# MKW38A4 register map
Vendor: NXP Semiconductors; Series: Kinetis_W; File version: 1.6
CPU: CM0PLUS r0p0, little endian, no MPU, no FPU, VTOR, 2 interrupt priority bits
Registers are 32-bit, read-write, no defined reset value unless marked. A register's access mark holds for its fields unless they carry their own. Offsets are from the block's base; [hi:lo] are bit positions; {n}, {i} and the like mark numbered series; 'fields as' and 'values as' point back to an identical list.

## XCVR_PLL_DIG
Base 0x40087600
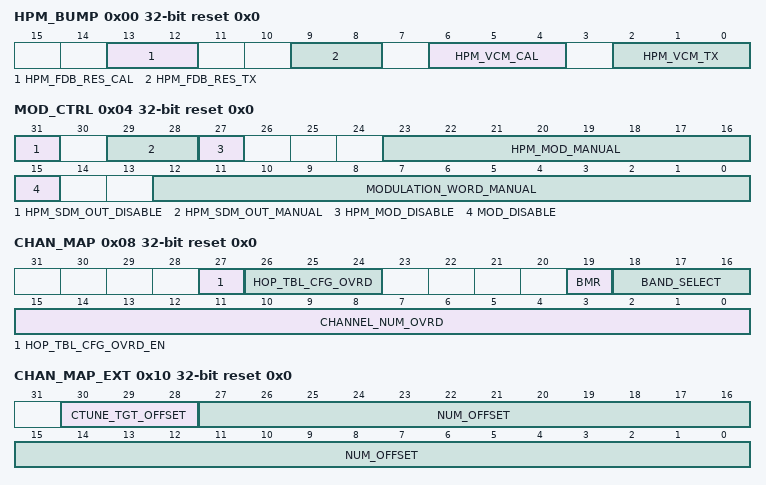
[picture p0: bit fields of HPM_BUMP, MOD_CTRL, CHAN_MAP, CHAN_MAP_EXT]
0x00 HPM_BUMP reset 0x0 — PLL HPM Analog Bump Control
  [13:12] HPM_FDB_RES_CAL — rfctrl_tx_dac_bump_fdb_res[1:0] during Calibration
    0=1.0; 1=0.5 (gain of 1/2); 2=1.17; 3=1.5
  [9:8] HPM_FDB_RES_TX — rfctrl_tx_dac_bump_fdb_res[1:0] during Transmission
    0=1.0; 1=0.5 (gain of 1/2); 2=1.17; 3=1.5
  [6:4] HPM_VCM_CAL — rfctrl_tx_dac_bump_vcm[2:0] during Calibration
    0=0.158; 1=0.193; 2=0.225; 3=0.255; 4=0.283; 5=0.309; 6=0.334; 7=0.357
  [2:0] HPM_VCM_TX — rfctrl_tx_dac_bump_vcm[2:0] during Transmission
    values as HPM_VCM_CAL
0x04 MOD_CTRL reset 0x0 — PLL Modulation Control
  [31] HPM_SDM_OUT_DISABLE — Disable HPM SDM out
  [29:28] HPM_SDM_OUT_MANUAL — Manual HPM SDM out
  [27] HPM_MOD_DISABLE — Disable HPM Modulation
  [23:16] HPM_MOD_MANUAL — Manual HPM Modulation
  [15] MOD_DISABLE — Disable Modulation Word
  [12:0] MODULATION_WORD_MANUAL — Manual Modulation Word
0x08 CHAN_MAP reset 0x0 — PLL Channel Mapping
  [27] HOP_TBL_CFG_OVRD_EN — Hop Table Configuration Override Enable
  [26:24] HOP_TBL_CFG_OVRD — Hop Table Configuration Override
    2=CHANNEL_NUM_OVRD[15:7] is signed Numerator offset to CHANNEL_NUM_OVRD[6:0] mapped channel number; 3=CHANNEL_NUM_OVRD[15:1] is selected as the signed Numerator, CHANNEL_NUM_OVRD[0] is integer selection
  [19] BMR — Bluetooth Low Energy MBAN Channel Remap
    0=Bluetooth Low Energy channel 39 is mapped to Bluetooth Low Energy channel 39, 2.480 GHz; 1=Bluetooth Low Energy channel 39 is mapped to MBAN channel 39, 2.399 GHz
  [18:16] BAND_SELECT — Channel Mapping Band Select
    0=Bluetooth Low Energy; 1=Bluetooth Low Energy in MBAN; 2=Bluetooth Low Energy overlap MBAN
  [15:0] CHANNEL_NUM_OVRD — Channel Selection Override
0x10 CHAN_MAP_EXT reset 0x0 — PLL Channel Mapping Extended
  [30:28] CTUNE_TGT_OFFSET — Coarse Tune Target Frequency Offset
  [27:0] NUM_OFFSET — Numerator Offset
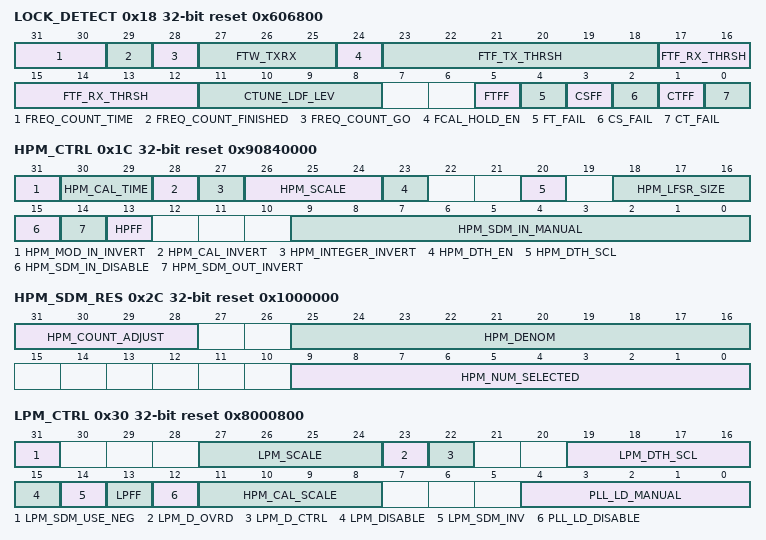
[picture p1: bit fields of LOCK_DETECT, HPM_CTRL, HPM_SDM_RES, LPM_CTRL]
0x18 LOCK_DETECT reset 0x606800 — PLL Lock Detect Control
  [31:30] FREQ_COUNT_TIME — Frequency Meter Count Time
    0=800 us; 1=25 us; 2=50 us; 3=100 us
  [29] FREQ_COUNT_FINISHED ro — Frequency Meter has finished the Count Time
  [28] FREQ_COUNT_GO — Start the Frequency Meter
  [27:25] FTW_TXRX — TX and RX Frequency Target Window time select
    0=FTW_TX = 4us ; FTW_RX = 4us; 1=FTW_TX = 4us ; FTW_RX = 8us; 2=FTW_TX = 8us ; FTW_RX = 4us; 3=FTW_TX = 8us ; FTW_RX = 8us; 4=FTW_TX = 16us ; FTW_RX = 16us; 5=FTW_TX = 16us ; FTW_RX = 32us; 6=FTW_TX = 32us ; FTW_RX = 16us; 7=FTW_TX = 32us ; FTW_RX = 32us
  [24] FCAL_HOLD_EN — Frequency Counter Hold Enable
    0=The frequency counter is turned off after CTUNE (RX Mode) or HPM CAL (TX Mode); 1=The frequency counter is held on after CTUNE (RX Mode) or HPM CAL (TX Mode) for an optional lock detect sequence
  [23:18] FTF_TX_THRSH — TX Frequency Target Fail Threshold
  [17:12] FTF_RX_THRSH — RX Frequency Target Fail Threshold
  [11:8] CTUNE_LDF_LEV — CTUNE Lock Detect Fail Level
  [5] FTFF — Frequency Target Failure Flag
  [4] FT_FAIL ro — Real time status of Frequency Target Failure
  [3] CSFF — Cycle Slip Failure Flag, held until cleared
  [2] CS_FAIL ro — Real time status of Cycle Slip circuit
  [1] CTFF — CTUNE Failure Flag, held until cleared
  [0] CT_FAIL ro — Real time status of Coarse Tune Fail signal
0x1C HPM_CTRL reset 0x90840000 — PLL High Port Modulator Control
  [31] HPM_MOD_IN_INVERT — Invert High Port Modulation
  [30:29] HPM_CAL_TIME — High Port Modulation Calibration Time
    0=25 us; 1=50 us; 2=100 us; 3=N/A
  [28] HPM_CAL_INVERT — Invert High Port Modulator Calibration
  [27] HPM_INTEGER_INVERT — Invert High Port Modulation Integer
  [26:24] HPM_SCALE — High Port Modulation Scale
    0=No Scaling; 1=Divide by 2; 2=Multiply by 2; 3=Multiply by 4; 4=Divide by 4
  [23] HPM_DTH_EN — Dither Enable for HPM LFSR
  [20] HPM_DTH_SCL — HPM Dither Scale
  [18:16] HPM_LFSR_SIZE — HPM LFSR Length
    0=LFSR 9, tap mask 100010000; 1=LFSR 10, tap mask 1001000000; 2=LFSR 11, tap mask 11101000000; 3=LFSR 13, tap mask 1101100000000; 4=LFSR 15, tap mask 111010000000000; 5=LFSR 17, tap mask 11110000000000000
  [15] HPM_SDM_IN_DISABLE — Disable HPM SDM Input
  [14] HPM_SDM_OUT_INVERT — Invert HPM SDM Output
  [13] HPFF — HPM SDM Invalid Flag
  [9:0] HPM_SDM_IN_MANUAL — Manual High Port SDM Fractional value
0x2C HPM_SDM_RES reset 0x1000000 — PLL High Port Sigma Delta Results
  [31:28] HPM_COUNT_ADJUST
  [25:16] HPM_DENOM — High Port Modulator SDM Denominator
  [9:0] HPM_NUM_SELECTED ro — High Port Modulator SDM Numerator
0x30 LPM_CTRL reset 0x8000800 — PLL Low Port Modulator Control
  [31] LPM_SDM_USE_NEG — Use the Negedge of the Sigma Delta clock
  [27:24] LPM_SCALE — LPM Scale Factor
    0=No Scaling; 1=Multiply by 2; 2=Multiply by 4; 3=Multiply by 8; 4=Multiply by 16; 5=Multiply by 32; 6=Multiply by 64; 7=Multiply by 128; 8=Multiply by 256; 9=Multiply by 512; 10=Multiply by 1024; 11=Multiply by 2048
  [23] LPM_D_OVRD — LPM Dither Override Mode Select
  [22] LPM_D_CTRL — LPM Dither Control in Override Mode
  [19:16] LPM_DTH_SCL — LPM Dither Scale
    5=-128 to 96; 6=-256 to 192; 7=-512 to 384; 8=-1024 to 768; 9=-2048 to 1536; 10=-4096 to 3072; 11=-8192 to 6144
  [15] LPM_DISABLE — Disable LPM SDM
  [14] LPM_SDM_INV — Invert LPM SDM
  [13] LPFF — LPM SDM Invalid Flag
  [12] PLL_LD_DISABLE — Disable PLL Loop Divider
  [11:8] HPM_CAL_SCALE — High Port Calibration Word Scaling
    3=Divide by 32; 4=Divide by 16; 5=Divide by 8; 6=Divide by 4; 7=Divide by 2; 8=No Scaling; 9=Multiply by 2; 10=Multiply by 4; 11=Multiply by 8
  [4:0] PLL_LD_MANUAL — Manual PLL Loop Divider value
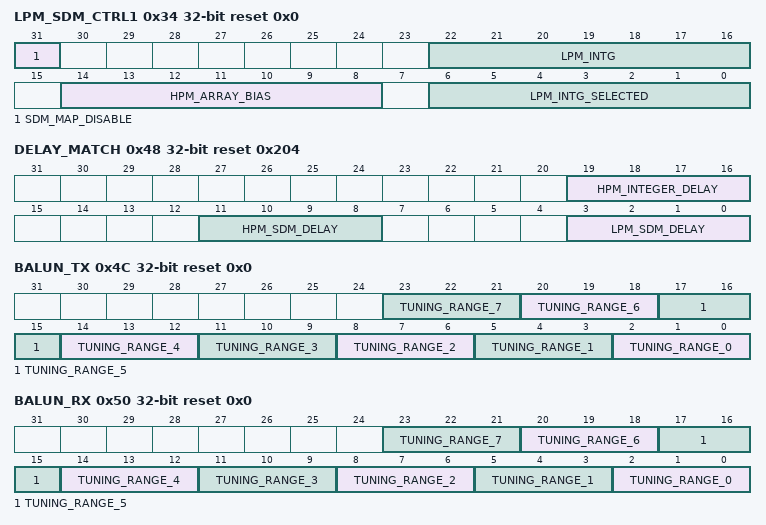
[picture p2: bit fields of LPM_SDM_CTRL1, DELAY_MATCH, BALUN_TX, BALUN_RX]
0x34 LPM_SDM_CTRL1 reset 0x0 — PLL Low Port Sigma Delta Control 1
  [31] SDM_MAP_DISABLE — Disable SDM Mapping
  [22:16] LPM_INTG — Manual Low Port Modulation Integer Value
  [14:8] HPM_ARRAY_BIAS — Bias value for High Port DAC Array Midpoint
  [6:0] LPM_INTG_SELECTED ro — Low Port Modulation Integer Value Selected
0x38 LPM_SDM_CTRL2 reset 0x2000000 — PLL Low Port Sigma Delta Control 2
  [27:0] LPM_NUM — Low Port Modulation Numerator
0x3C LPM_SDM_CTRL3 reset 0x4000000 — PLL Low Port Sigma Delta Control 3
  [27:0] LPM_DENOM — Low Port Modulation Denominator
0x40 LPM_SDM_RES1 ro reset 0xE200000 — PLL Low Port Sigma Delta Result 1
  [27:0] LPM_NUM_SELECTED — Low Port Modulation Numerator Applied
0x44 LPM_SDM_RES2 ro reset 0x4000000 — PLL Low Port Sigma Delta Result 2
  [27:0] LPM_DENOM_SELECTED — Low Port Modulation Denominator Selected
0x48 DELAY_MATCH reset 0x204 — PLL Delay Matching
  [19:16] HPM_INTEGER_DELAY — High Port Integer Delay Matching
  [11:8] HPM_SDM_DELAY — High Port SDM Delay Matching
  [3:0] LPM_SDM_DELAY — Low Port SDM Delay Matching
0x4C BALUN_TX reset 0x0 — Balun Tuning Cap Settings in Transmit Mode
  [3n+2:3n] TUNING_RANGE_{n} (n=0..7)
0x50 BALUN_RX reset 0x0 — Balun Tuning Cap Settings in Receive Mode
  [3n+2:3n] TUNING_RANGE_{n} (n=0..7)
0x58 MAX_TX_CFG1_FREQ reset 0xFFF — Max Transmit Frequency For TX Configuration 1
  [11:0] MAX_TX_CFG1_FREQ — Maximum Transmit Frequency for Standard TX Settings
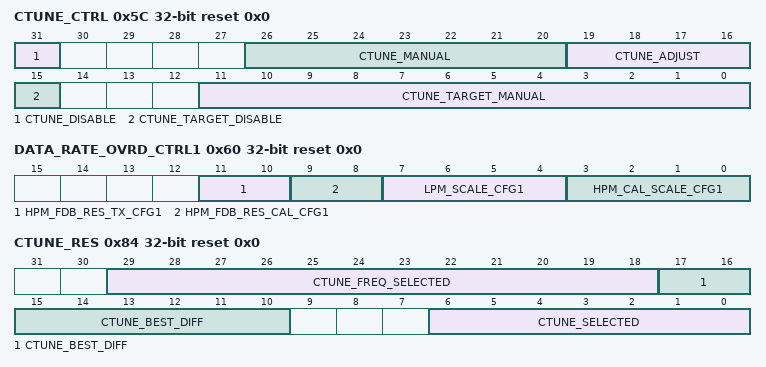
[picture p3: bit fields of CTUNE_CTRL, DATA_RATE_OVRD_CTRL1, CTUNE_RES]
0x5C CTUNE_CTRL reset 0x0 — PLL Coarse Tune Control
  [31] CTUNE_DISABLE — Coarse Tune Disable
  [26:20] CTUNE_MANUAL — Manual Coarse Tune Setting
  [19:16] CTUNE_ADJUST — Coarse Tune Count Adjustment
  [15] CTUNE_TARGET_DISABLE — Disable Coarse Tune Target
  [11:0] CTUNE_TARGET_MANUAL — Manual Coarse Tune Target
0x60 DATA_RATE_OVRD_CTRL1 reset 0x0 — PLL Data Rate Override Control
  [11:10] HPM_FDB_RES_TX_CFG1 — HPM FDB RES Transmit Configuration1
  [9:8] HPM_FDB_RES_CAL_CFG1 — HPM FDB RES Calibration Configuration1
  [7:4] LPM_SCALE_CFG1 — LPM Scale Configuration1
  [3:0] HPM_CAL_SCALE_CFG1 — HPM Scale Configuration1
0x84 CTUNE_RES ro reset 0x0 — PLL Coarse Tune Results
  [29:18] CTUNE_FREQ_SELECTED — Coarse Tune Frequency Selected
  [17:10] CTUNE_BEST_DIFF — Coarse Tune Absolute Best Difference
  [6:0] CTUNE_SELECTED — Coarse Tune Setting to VCO
